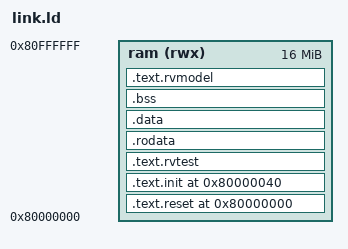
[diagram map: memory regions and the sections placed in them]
/* Set these to match the DUT memory map and hart count. */
RAM_ORIGIN = 0x80000000;
RAM_LENGTH = 0x1000000;
TEST_BASE = RAM_ORIGIN;
NUM_HARTS = 1;

/* Most users should not need to modify anything below this line. */
STACK_SIZE = 0x20000;

OUTPUT_ARCH( "riscv" )
ENTRY(__rvw_reset)

MEMORY
{
  ram (rwx) : ORIGIN = RAM_ORIGIN, LENGTH = RAM_LENGTH
}

PROVIDE(__stack_size = STACK_SIZE);
PROVIDE(__num_harts = NUM_HARTS);

SECTIONS
{
  ASSERT(TEST_BASE >= ORIGIN(ram) && TEST_BASE < ORIGIN(ram) + LENGTH(ram), "TEST_BASE is outside RAM; update TEST_BASE and RAM_ORIGIN/RAM_LENGTH in link.ld, and the matching memory.regions entry in sail.json")

  /* Execute reset-state initialization before C2's first CSR snapshot.
     No comparator mask or synchronization is needed. Both models execute it. */
  .text.reset TEST_BASE : {
    __rvw_reset = .;
    LONG(0x34001073) /* csrw mscratch, zero */
    LONG(0x30501073) /* csrw mtvec, zero */
    LONG(0x0380006f) /* jal zero, +56: .text.init at TEST_BASE + 64 */
  } > ram
  .text.init   (TEST_BASE + 64) : { *(.text.init) } > ram
  .text.rvtest . : { *(.text.rvtest) *(.text.rvtest.*) } > ram

  . = ALIGN(0x4000);
  .rodata . : { *(.rodata) *(.rodata.*) *(.srodata) *(.srodata.*) } > ram
  .data   . : { *(.data) *(.data.*) *(.sdata) *(.sdata.*) } > ram

  . = ALIGN(16);
  .bss . : {
    __bss_start = .;
    *(.sbss) *(.sbss.*) *(.bss) *(.bss.*) *(COMMON)
    . = ALIGN(16);
    __bss_end = .;
  } > ram

  . = ALIGN(16);
  __stack_bottom = .;
  . += __stack_size * __num_harts;
  __stack_top = .;

  . = ALIGN(0x1000);
  .text.rvmodel . : { *(.text.rvmodel) *(.text.rvmodel.*) *(.text) *(.text.*) } > ram

  . = ALIGN(0x1000);
  _end = .;

  ASSERT(_end <= ORIGIN(ram) + LENGTH(ram), "ACT ELF exceeds RAM; increase RAM_LENGTH in link.ld and the matching memory.regions size in sail.json")
}
